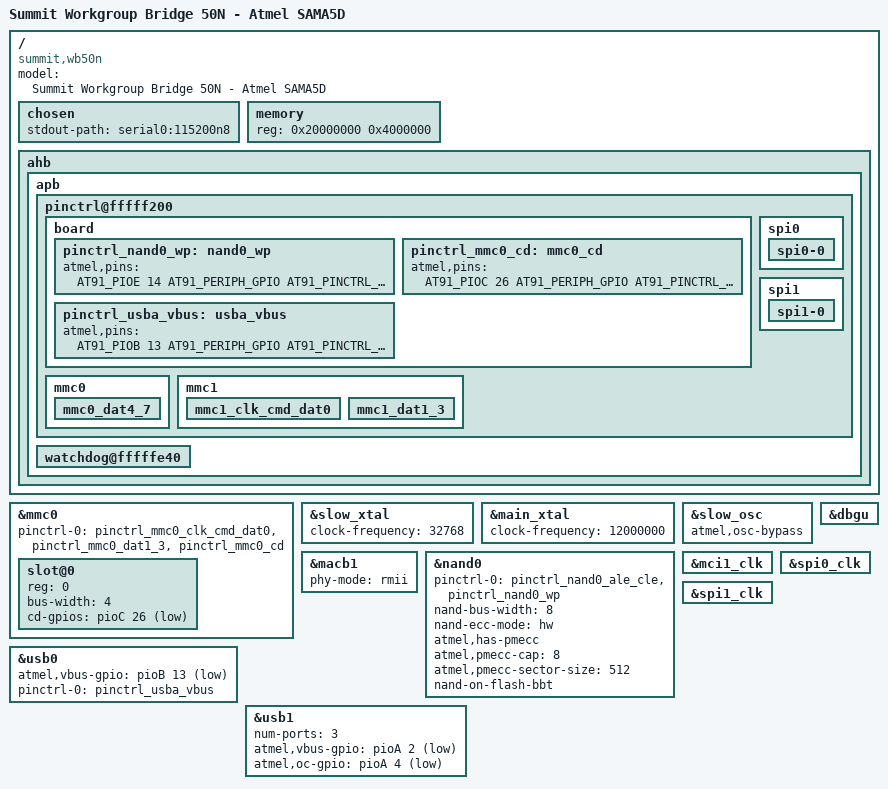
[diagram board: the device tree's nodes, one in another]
// SPDX-License-Identifier: LicenseRef-Ezurio-Clause
/*
 * at91-wb50n_common.dtsi - Device Tree file for the WB50n module
 *
 * Copyright (C) 2018 Ezurio
 */

#include "sama5d31.dtsi"

/ {
	model = "Summit Workgroup Bridge 50N - Atmel SAMA5D";
	compatible = "summit,wb50n", "atmel,sama5d31", "atmel,sama5d3", "atmel,sama5";

	chosen {
		stdout-path = "serial0:115200n8";
	};

	memory {
		reg = <0x20000000 0x4000000>;
	};

	ahb {
		apb {
			pinctrl@fffff200 {
				board {
					bootph-all;
					pinctrl_nand0_wp: nand0_wp {
						atmel,pins = <AT91_PIOE 14 AT91_PERIPH_GPIO AT91_PINCTRL_NONE>;
					};

					pinctrl_mmc0_cd: mmc0_cd {
						bootph-all;
						atmel,pins = <AT91_PIOC 26 AT91_PERIPH_GPIO AT91_PINCTRL_PULL_UP_DEGLITCH>; /* PC26 GPIO with pullup deglitch */
					};

					pinctrl_usba_vbus: usba_vbus {
						atmel,pins = <AT91_PIOB 13 AT91_PERIPH_GPIO AT91_PINCTRL_DEGLITCH>; /* PB13 GPIO with deglitch */
					};
				};

				mmc0 {
					mmc0_dat4_7 {
						/delete-node/ bootph-all;
					};
				};

				mmc1 {
					/delete-property/ bootph-all;
					mmc1_clk_cmd_dat0 {
						/delete-property/ bootph-all;
					};

					mmc1_dat1_3 {
						/delete-property/ bootph-all;
					};
				};

				spi0 {
					/delete-property/ bootph-all;
					spi0-0 {
						/delete-property/ bootph-all;
					};
				};

				spi1 {
					/delete-property/ bootph-all;
					spi1-0 {
						/delete-property/ bootph-all;
					};
				};
			};
/*
			sha@f8034000 {
				bootph-all;
			};
*/
			watchdog@fffffe40 {
				bootph-all;
				status = "okay";
			};
		};
	};
};

&mmc0 {
	pinctrl-names = "default";
	pinctrl-0 = <&pinctrl_mmc0_clk_cmd_dat0 &pinctrl_mmc0_dat1_3 &pinctrl_mmc0_cd>;

	slot@0 {
		reg = <0>;
		bus-width = <4>;
		cd-gpios = <&pioC 26 GPIO_ACTIVE_LOW>;
	};
};

&slow_xtal {
	clock-frequency = <32768>;
};

&main_xtal {
	clock-frequency = <12000000>;
};

&slow_osc {
	atmel,osc-bypass;
};

&macb1 {
	phy-mode = "rmii";
};

&dbgu {
	bootph-all;
	status = "okay";
};

&nand0 {
	pinctrl-0 = <&pinctrl_nand0_ale_cle &pinctrl_nand0_wp>;
	nand-bus-width = <8>;
	nand-ecc-mode = "hw";
	atmel,has-pmecc;
	atmel,pmecc-cap = <8>;
	atmel,pmecc-sector-size = <512>;

	/*
	 * Note - nand-on-flash-bbt requires the last 4 blocks on
	 * flash to be reserved for bad block table.  These blocks
	 * can be used in partitions only if bbt is not stored on flash.
	 */
	nand-on-flash-bbt;
	status = "okay";
};

&usb0 {
	atmel,vbus-gpio = <&pioB 13 GPIO_ACTIVE_LOW>;
	pinctrl-names = "default";
	pinctrl-0 = <&pinctrl_usba_vbus>;
};

&usb1 {
	num-ports = <3>;
	atmel,vbus-gpio = <&pioA 2 GPIO_ACTIVE_LOW>;
	atmel,oc-gpio = <&pioA 4 GPIO_ACTIVE_LOW>;
};
/*
&sha_clk {
	bootph-all;
};
*/
&mci1_clk {
	/delete-property/ bootph-all;
};

&spi0_clk {
	/delete-property/ bootph-all;
};

&spi1_clk {
	/delete-property/ bootph-all;
};
